# PIC32MM0016GPL036 device description
Architecture: MIPS; Family: PIC32MM1324; Series: PIC32MM
Registers are 32-bit, read-write, no defined reset value unless marked. A register's access mark holds for its fields unless they carry their own. Offsets are from the block's base; [hi:lo] are bit positions; 'fields as' and 'values as' point back to an identical list.

## RTCC
Instances: RTCC 0x1f800000 in periph0
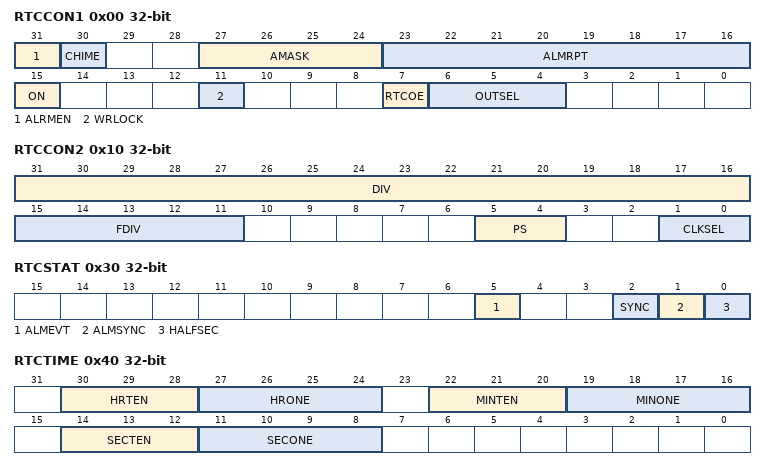
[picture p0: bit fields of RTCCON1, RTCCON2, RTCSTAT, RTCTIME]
0x00 RTCCON1
  [31] ALRMEN
  [30] CHIME
  [27:24] AMASK — Alarm Mask Configuration bits
    0=Every half-second; 1=Every second; 2=Every 10 seconds; 3=Every minute; 4=Every 10 minutes; 5=Every hour; 6=Once a day; 7=Once a week; 8=Once a month; 9=Once a year (or once every four years when configured for February 29th)
  [23:16] ALMRPT — Alarm Repeat Counter Value bits
  [15] ON — RTCC On bit
    1=RTCC module is enabled; 0=RTCC module is disabled
  [11] WRLOCK
  [7] RTCOE — RTCC Output Enable bit
    1=RTCC clock output is enabled; signal selected by OUTSEL[2:0] is presented on the RTCC pin; 0=RTCC clock output is disabled
  [6:4] OUTSEL — RTCC Signal Output Select bits
    2=RTCC input clock source (based on the combination of the RTCCON2 bits, DIV[15:0] and PS[1:0]); 1=Seconds Clock is presented on the RTCC pin; 0=Alarm Pulse is presented on the RTCC pin when the alarm interrupt is triggered
0x10 RTCCON2
  [31:16] DIV
  [15:11] FDIV
  [5:4] PS — RTCC Prescaler
    3=1:256; 2=1:64; 1=1:16; 0=1:1
  [1:0] CLKSEL — RTCC Clock Select bits
    3=PBCLK (RTCC uses peripheral clock); 2=PWRLCLK (RTCC uses the clock on PWRLCLK pin); 1=LPRC (RTCC uses the internal 32 kHz oscillator (LPRC)); 0=SOSC (RTCC uses the external 32.768 kHz Secondary Oscillator (SOSC))
0x30 RTCSTAT ro
  [5] ALMEVT, [2] SYNC, [1] ALMSYNC, [0] HALFSEC
0x40 RTCTIME
  [30:28] HRTEN, [27:24] HRONE, [22:20] MINTEN, [19:16] MINONE, [14:12] SECTEN, [11:8] SECONE
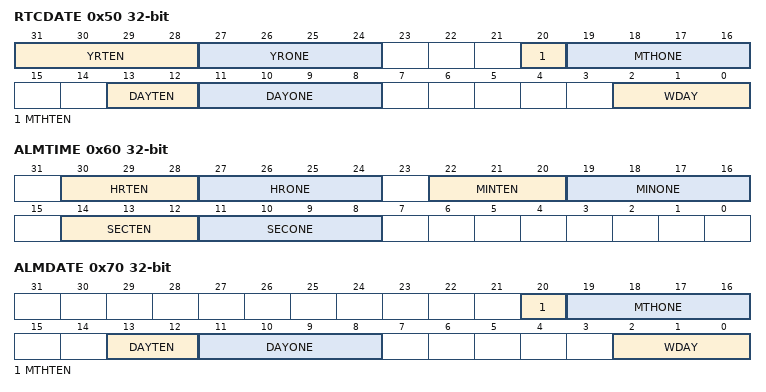
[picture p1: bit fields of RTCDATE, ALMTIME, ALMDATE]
0x50 RTCDATE
  [31:28] YRTEN, [27:24] YRONE, [20] MTHTEN, [19:16] MTHONE, [13:12] DAYTEN, [11:8] DAYONE, [2:0] WDAY
0x60 ALMTIME
  fields as RTCTIME
0x70 ALMDATE
  [20] MTHTEN, [19:16] MTHONE, [13:12] DAYTEN, [11:8] DAYONE, [2:0] WDAY

## TMR1
Instances: TMR1 0x1f808000 in periph1
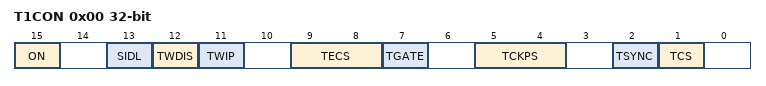
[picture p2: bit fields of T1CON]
0x00 T1CON — TYPE A TIMER CONTROL REGISTER
  [15] ON — Timer On bit
    1=Timer is enabled; 0=Timer is disabled
  [13] SIDL — Stop in Idle Mode bit
    1=Discontinue operation when device enters Idle mode; 0=Continue operation even in Idle mode
  [12] TWDIS — Asynchronous Timer Write Disable bit
    1=Writes to TMR1 are ignored until pending write operation completes; 0=Back-to-back writes are enabled (Legacy Asynchronous Timer functionality)
  [11] TWIP — Asynchronous Timer Write in Progress bit
    1=(In Asynchronous Timer mode) Asynchronous write to TMR1 register in progress / (In Synchronous Timer mode)bit is read as 0; 0=In Asynchronous Timer mode Asynchronous write to TMR1 register complete / (In Synchronous Timer mode)bit is read as 0
  [9:8] TECS — Timer1 External Clock Selection bits
    2=LPRC (External clock comes from the LPRC); 1=T1CK_PIN (External clock comes from the T1CK pin); 0=SOSC (External clock comes from the SOSC)
  [7] TGATE — Timer Gated Time Accumulation Enable bit
    1=(When TCS is 0) Gated time accumulation is enabled / (When TCS is 1) bit is ignored; 0=(When TCS is 0) Gated time accumulation is disabled / (When TCS is 1) bit is ignored
  [5:4] TCKPS — Timer Input Clock Prescale Select bits
    3=1:256 prescale value; 2=1:64 prescale value; 1=1:8 prescale value; 0=1:1 prescale value
  [2] TSYNC — Timer External Clock Input Synchronization Selection bit
    1=(When TCS is 1) External clock input is synchronized / (When TCS is 0) This bit is ignored; 0=(When TCS is 1) External clock input is not synchronized / (When TCS is 0) This bit is ignored
  [1] TCS — Timer Clock Source Select bit
    1=External clock is defined by the TECS bits; 0=Internal peripheral clock
0x10 TMR1
0x20 PR1

## UDID
Instances: UDID 0x1fc41840 in UDIDx
0x00 UDID1 ro
0x04 UDID2 ro
0x08 UDID3 ro
0x0C UDID4 ro
0x10 UDID5 ro

## WDT
Instances: WDT 0x1f803e80 in periph0
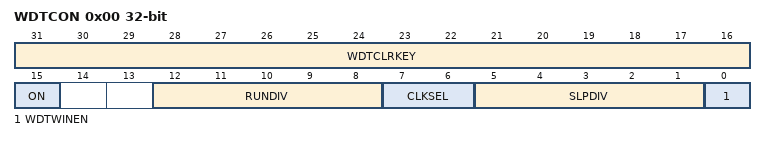
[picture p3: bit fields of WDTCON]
0x00 WDTCON — Watchdog Timer Control Register
  [31:16] WDTCLRKEY — Watchdog Timer Clear Key bits
  [15] ON — Watchdog Timer Enable bit
    1=The WDT module is enabled; 0=The WDT module is disabled
  [12:8] RUNDIV — Watchdog Timer Postscaler Value in Run Mode bits
  [7:6] CLKSEL
  [5:1] SLPDIV
  [0] WDTWINEN — Watchdog Timer Window Enable bit
    1=Enable windowed Watchdog Timer; 0=Disable windowed Watchdog Timer

## Notices in the file
Copyright (c) 2019 Microchip Technology Inc.
SPDX-License-Identifier: Apache-2.0
Licensed under the Apache License, Version 2.0 (the "License");
you may not use this file except in compliance with the License.
You may obtain a copy of the License at
http://www.apache.org/licenses/LICENSE-2.0
Unless required by applicable law or agreed to in writing, software
distributed under the License is distributed on an "AS IS" BASIS,
WITHOUT WARRANTIES OR CONDITIONS OF ANY KIND, either express or implied.
See the License for the specific language governing permissions and
limitations under the License.
